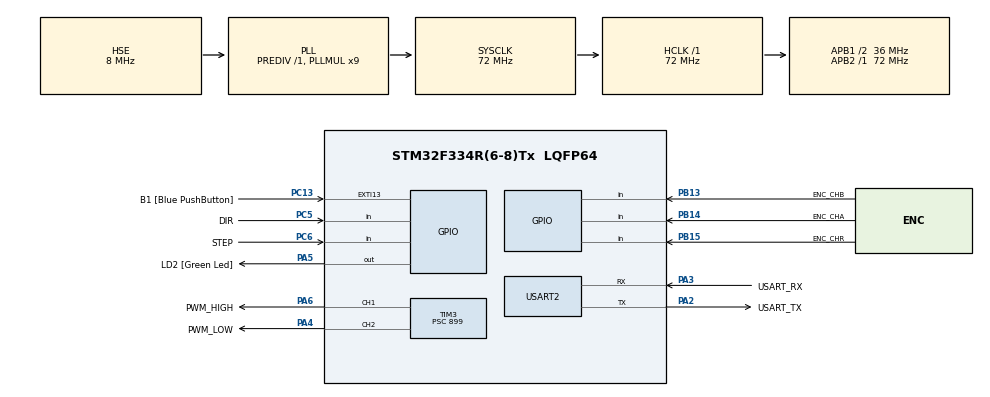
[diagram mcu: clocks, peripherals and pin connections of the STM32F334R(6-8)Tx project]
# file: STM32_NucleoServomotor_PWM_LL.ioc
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Mcu.Family=STM32F3
Mcu.Name=STM32F334R(6-8)Tx
Mcu.Package=LQFP64
NVIC.PriorityGroup=NVIC_PRIORITYGROUP_0
PA13.GPIO_Label=TMS
PA13.Mode=Serial_Wire
PA13.Signal=SYS_JTMS-SWDIO
PA14.GPIO_Label=TCK
PA14.Mode=Serial_Wire
PA14.Signal=SYS_JTCK-SWCLK
PA2.GPIO_Label=USART_TX
PA2.Mode=Asynchronous
PA2.Signal=USART2_TX
PA3.GPIO_Label=USART_RX
PA3.Mode=Asynchronous
PA3.Signal=USART2_RX
PA4.GPIO_Label=PWM_LOW
PA4.Signal=S_TIM3_CH2
PA5.GPIO_Label=LD2 [Green Led]
PA5.Signal=GPIO_Output
PA6.GPIO_Label=PWM_HIGH
PA6.Signal=S_TIM3_CH1
PB13.GPIO_Label=ENC_CHB
PB13.Signal=GPIO_Input
PB14.GPIO_Label=ENC_CHA
PB14.Signal=GPIO_Input
PB15.GPIO_Label=ENC_CHR
PB15.Signal=GPIO_Input
PB3.GPIO_Label=SWO
PB3.Signal=SYS_JTDO-TRACESWO
PC13.GPIO_Label=B1 [Blue PushButton]
PC13.GPIO_ModeDefaultEXTI=GPIO_MODE_IT_FALLING
PC13.Signal=GPXTI13
PC14\ /\ OSC32_IN.Mode=LSE-External-Oscillator
PC14\ /\ OSC32_IN.Signal=RCC_OSC32_IN
PC15\ /\ OSC32_OUT.GPIO_Label=RCC_OSC32_OUT
PC15\ /\ OSC32_OUT.Mode=LSE-External-Oscillator
PC15\ /\ OSC32_OUT.Signal=RCC_OSC32_OUT
PC5.GPIO_Label=DIR
PC5.Signal=GPIO_Input
PC6.GPIO_Label=STEP
PC6.Signal=GPIO_Input
PF0\ /\ OSC_IN.Mode=HSE-External-Clock-Source
PF0\ /\ OSC_IN.Signal=RCC_OSC_IN
PF1\ /\ OSC_OUT.Signal=RCC_OSC_OUT
ProjectManager.HeapSize=0x200
ProjectManager.StackSize=0x400
ProjectManager.TargetToolchain=TrueSTUDIO
RCC.AHBFreq_Value=72000000
RCC.APB1CLKDivider=RCC_HCLK_DIV2
RCC.APB1Freq_Value=36000000
RCC.APB1TimFreq_Value=72000000
RCC.APB2Freq_Value=72000000
RCC.APB2TimFreq_Value=72000000
RCC.CortexFreq_Value=72000000
RCC.FLatency-AdvancedSettings=FLASH_LATENCY_2
RCC.HCLKFreq_Value=72000000
RCC.HSE_VALUE=8000000
RCC.HSI_VALUE=8000000
RCC.PLLMUL=RCC_PLL_MUL9
RCC.PLLSourceVirtual=RCC_PLLSOURCE_HSE
RCC.SYSCLKFreq_VALUE=72000000
RCC.SYSCLKSourceVirtual=RCC_SYSCLKSOURCE_PLLCLK
SH.S_TIM3_CH1.0=TIM3_CH1,PWM Generation1 CH1
SH.S_TIM3_CH2.0=TIM3_CH2,PWM Generation2 CH2
TIM3.Channel-PWM\ Generation1\ CH1=TIM_CHANNEL_1
TIM3.Channel-PWM\ Generation2\ CH2=TIM_CHANNEL_2
TIM3.Period=3
TIM3.Prescaler=899
USART2.VirtualMode-Asynchronous=VM_ASYNC
VP_TIM3_VS_ClockSourceINT.Mode=Internal
board=NUCLEO-F334R8

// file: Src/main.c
/* USER CODE BEGIN Header */
/**
  ******************************************************************************
  * @file           : main.c
  * @brief          : Main program body
  ******************************************************************************
  ** This notice applies to any and all portions of this file
  * that are not between comment pairs USER CODE BEGIN and
  * USER CODE END. Other portions of this file, whether
  * inserted by the user or by software development tools
  * are owned by their respective copyright owners.
  *
  * COPYRIGHT(c) 2020 STMicroelectronics
  *
  * Redistribution and use in source and binary forms, with or without modification,
  * are permitted provided that the following conditions are met:
  *   1. Redistributions of source code must retain the above copyright notice,
  *      this list of conditions and the following disclaimer.
  *   2. Redistributions in binary form must reproduce the above copyright notice,
  *      this list of conditions and the following disclaimer in the documentation
  *      and/or other materials provided with the distribution.
  *   3. Neither the name of STMicroelectronics nor the names of its contributors
  *      may be used to endorse or promote products derived from this software
  *      without specific prior written permission.
  *
  * THIS SOFTWARE IS PROVIDED BY THE COPYRIGHT HOLDERS AND CONTRIBUTORS "AS IS"
  * AND ANY EXPRESS OR IMPLIED WARRANTIES, INCLUDING, BUT NOT LIMITED TO, THE
  * IMPLIED WARRANTIES OF MERCHANTABILITY AND FITNESS FOR A PARTICULAR PURPOSE ARE
  * DISCLAIMED. IN NO EVENT SHALL THE COPYRIGHT HOLDER OR CONTRIBUTORS BE LIABLE
  * FOR ANY DIRECT, INDIRECT, INCIDENTAL, SPECIAL, EXEMPLARY, OR CONSEQUENTIAL
  * DAMAGES (INCLUDING, BUT NOT LIMITED TO, PROCUREMENT OF SUBSTITUTE GOODS OR
  * SERVICES; LOSS OF USE, DATA, OR PROFITS; OR BUSINESS INTERRUPTION) HOWEVER
  * CAUSED AND ON ANY THEORY OF LIABILITY, WHETHER IN CONTRACT, STRICT LIABILITY,
  * OR TORT (INCLUDING NEGLIGENCE OR OTHERWISE) ARISING IN ANY WAY OUT OF THE USE
  * OF THIS SOFTWARE, EVEN IF ADVISED OF THE POSSIBILITY OF SUCH DAMAGE.
  *
  ******************************************************************************
  */
/* USER CODE END Header */

#include "main.h"
#include "tim.h"
#include "usart.h"
#include "gpio.h"
#include "arm_math.h"

void CNC_PollSignal_2(void);
void SystemClock_Config(void);

#define PID_PARAM_KP        100            /* Proporcional */
#define PID_PARAM_KI        0.025        /* Integral */
#define PID_PARAM_KD        21            /* Derivative */
#define SERVO_MAX_ERR		40

volatile int32_t Axis_Pos = 0;
volatile int32_t Set_Pos = 0;

volatile int Flag_rotation = 0;
volatile long Aux_Axis_Pos = 0;
float Dac_voltaje = 0.0;
int Flag_Invert = 0;
uint32_t var;
uint16_t OutputScaled = 0;
int main(void)
{
  /* USER CODE BEGIN 1 */
	  int32_t Err_In  = 0;
	  float32_t Out_Response = 0;
  /* USER CODE END 1 */

  /* MCU Configuration--------------------------------------------------------*/

  /* Reset of all peripherals, Initializes the Flash interface and the Systick. */
  HAL_Init();

  /* Configure the system clock */
  SystemClock_Config();

  /* Initialize all configured peripherals */
  MX_GPIO_Init();
  MX_USART2_UART_Init();
  MX_TIM3_Init();
  arm_pid_instance_f32 PID;
  PID.Kp = PID_PARAM_KP;        /* Proporcional */
  PID.Ki = PID_PARAM_KI;        /* Integral */
  PID.Kd = PID_PARAM_KD;        /* Derivative */

  arm_pid_init_f32(&PID, 1);

  HAL_TIM_PWM_Start(&htim3,TIM_CHANNEL_1);
  HAL_TIM_PWM_Start(&htim3,TIM_CHANNEL_2);
  TIM3->CCR2 = 0;
  TIM3->CCR1 = 0;
  /* Infinite loop */
  while (1)
  {
	CNC_PollSignal_2();
	if(Axis_Pos >= Set_Pos)
	{
		Err_In = Axis_Pos - Set_Pos;//update error
		Flag_Invert = 0;
	}
	else
	{
		Err_In = Set_Pos - Axis_Pos;//update error
		Flag_Invert = 1;
	}
	if(Err_In >= SERVO_MAX_ERR)
	{
		Out_Response = arm_pid_f32(&PID, Err_In);

		if(Out_Response > 4095) Out_Response = 4095;
		if(Out_Response < 0) Out_Response = 0;

		OutputScaled = Out_Response;

		if(Flag_Invert)
		{
			//Out_Response = 2048 - Out_Response;
			//TIM3->CCR2 = (Out_Response << 4)|(Out_Response >> (28));
			TIM3->CCR2 = OutputScaled << 4;
			TIM3->CCR1 = 0;
		}
		else
		{
			TIM3->CCR2 = 0;
			TIM3->CCR1 = OutputScaled << 4;
			//TIM3->CCR1 = (Out_Response << 4)|(Out_Response >> (28));
			//Out_Response = 2048 + Out_Response;
		}

		//LL_DAC_ConvertData12RightAligned(DAC1, LL_DAC_CHANNEL_1, Out_Response);
		//LL_DAC_TrigSWConversion(DAC1, LL_DAC_CHANNEL_1);
	}
  }
  /* USER CODE END 3 */
}

void CNC_PollSignal_2(void)
{
	//estados anteriores de las terminales del controlador
	static GPIO_PinState CNT_StepPin_Old_State;
	//static GPIO_PinState CNT_DirPin_Old_State;
	//estados anteriores de las terminales del encoder
	static GPIO_PinState ENC_APin_Old_State;
	static GPIO_PinState ENC_BPin_Old_State;
	static GPIO_PinState ENC_RotPin_Old_State;

	//estados actuales de las terminales del controlador
	GPIO_PinState CNT_StepPin_State;
	GPIO_PinState CNT_DirPin_State;
	//estados actuales de las terminales del encoder
	GPIO_PinState ENC_APin_State;
	GPIO_PinState ENC_BPin_State;
	GPIO_PinState ENC_RotPin_State;

	CNT_StepPin_State = LL_GPIO_IsInputPinSet(STEP_GPIO_Port,STEP_Pin);
	CNT_DirPin_State = LL_GPIO_IsInputPinSet(DIR_GPIO_Port,DIR_Pin);
	ENC_APin_State = LL_GPIO_IsInputPinSet(ENC_CHA_GPIO_Port,ENC_CHA_Pin);
	ENC_BPin_State = LL_GPIO_IsInputPinSet(ENC_CHB_GPIO_Port,ENC_CHB_Pin);
	ENC_RotPin_State = LL_GPIO_IsInputPinSet(ENC_CHR_GPIO_Port,ENC_CHR_Pin);

	if(CNT_StepPin_State != CNT_StepPin_Old_State)
	{
		if(CNT_StepPin_State == GPIO_PIN_SET)
		{
			if(CNT_DirPin_State == GPIO_PIN_SET)Set_Pos++;
			else Set_Pos --;
		}
		CNT_StepPin_Old_State = CNT_StepPin_State;
	}

	if(ENC_APin_State != ENC_APin_Old_State)
	{

		if(ENC_APin_State == GPIO_PIN_SET && ENC_BPin_State == GPIO_PIN_SET) Axis_Pos ++;
		if(ENC_APin_State == GPIO_PIN_RESET && ENC_BPin_State == GPIO_PIN_SET) Axis_Pos --;
		if(ENC_APin_State == GPIO_PIN_SET && ENC_BPin_State == GPIO_PIN_RESET) Axis_Pos --;
		if(ENC_APin_State == GPIO_PIN_RESET && ENC_BPin_State == GPIO_PIN_RESET) Axis_Pos ++;

		ENC_APin_Old_State = ENC_APin_State;
	}

	if(ENC_BPin_State != ENC_BPin_Old_State)
	{
		if(ENC_APin_State == GPIO_PIN_SET && ENC_BPin_State == GPIO_PIN_SET) Axis_Pos --;
		if(ENC_APin_State == GPIO_PIN_RESET && ENC_BPin_State == GPIO_PIN_SET) Axis_Pos ++;
		if(ENC_APin_State == GPIO_PIN_SET && ENC_BPin_State == GPIO_PIN_RESET) Axis_Pos ++;
		if(ENC_APin_State == GPIO_PIN_RESET && ENC_BPin_State == GPIO_PIN_RESET) Axis_Pos --;
		ENC_BPin_Old_State = ENC_BPin_State;
	}
	//Por implementar
	if(ENC_RotPin_State != ENC_RotPin_Old_State)
	{
		if(ENC_RotPin_State == GPIO_PIN_SET)
		{
			Aux_Axis_Pos = Axis_Pos;
			Axis_Pos = 0;
			Flag_rotation = 1;
		}
		//Sucede cuando el motor da una rotacion
		ENC_RotPin_Old_State = ENC_RotPin_State;
	}
	//HAL_GPIO_TogglePin(LD2_GPIO_Port, LD2_Pin);
	LL_GPIO_TogglePin(LD2_GPIO_Port, LD2_Pin);
	//HAL_GPIO_WritePin(GPIOB,GPIO_PIN_13,GPIO_PIN_SET);
	//HAL_GPIO_ReadPin(GPIOB,GPIO_PIN_12)== 0
	//HAL_
}

void SystemClock_Config(void)
{
  RCC_OscInitTypeDef RCC_OscInitStruct = {0};
  RCC_ClkInitTypeDef RCC_ClkInitStruct = {0};

  /**Initializes the CPU, AHB and APB busses clocks
  */
  RCC_OscInitStruct.OscillatorType = RCC_OSCILLATORTYPE_HSE;
  RCC_OscInitStruct.HSEState = RCC_HSE_BYPASS;
  RCC_OscInitStruct.HSEPredivValue = RCC_HSE_PREDIV_DIV1;
  RCC_OscInitStruct.HSIState = RCC_HSI_ON;
  RCC_OscInitStruct.PLL.PLLState = RCC_PLL_ON;
  RCC_OscInitStruct.PLL.PLLSource = RCC_PLLSOURCE_HSE;
  RCC_OscInitStruct.PLL.PLLMUL = RCC_PLL_MUL9;
  if (HAL_RCC_OscConfig(&RCC_OscInitStruct) != HAL_OK)
  {
    Error_Handler();
  }
  /**Initializes the CPU, AHB and APB busses clocks
  */
  RCC_ClkInitStruct.ClockType = RCC_CLOCKTYPE_HCLK|RCC_CLOCKTYPE_SYSCLK
                              |RCC_CLOCKTYPE_PCLK1|RCC_CLOCKTYPE_PCLK2;
  RCC_ClkInitStruct.SYSCLKSource = RCC_SYSCLKSOURCE_PLLCLK;
  RCC_ClkInitStruct.AHBCLKDivider = RCC_SYSCLK_DIV1;
  RCC_ClkInitStruct.APB1CLKDivider = RCC_HCLK_DIV2;
  RCC_ClkInitStruct.APB2CLKDivider = RCC_HCLK_DIV1;

  if (HAL_RCC_ClockConfig(&RCC_ClkInitStruct, FLASH_LATENCY_2) != HAL_OK)
  {
    Error_Handler();
  }
}

void Error_Handler(void)
{
}

/************************ (C) COPYRIGHT STMicroelectronics *****END OF FILE****/
